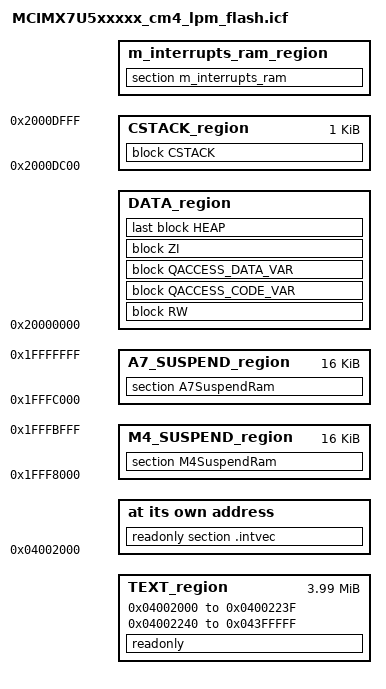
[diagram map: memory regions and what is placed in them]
/*
** ###################################################################
**     Processors:          MCIMX7U5DVK08
**                          MCIMX7U5DVP08
**
**     Compiler:            IAR ANSI C/C++ Compiler for ARM
**     Reference manual:    i.MX7ULPRMV2, Rev. A, Dec. 2017
**     Version:             rev. 5.0, 2017-12-22
**     Build:               b171222
**
**     Abstract:
**         Linker file for the IAR ANSI C/C++ Compiler for ARM
**
**     Copyright 2016 Freescale Semiconductor, Inc.
**     Copyright 2016-2017 NXP
**     All rights reserved.
**
**     SPDX-License-Identifier: BSD-3-Clause
**
**     http:                 www.nxp.com
**     mail:                 support@nxp.com
**
** ###################################################################
*/

/* Memory region from [0x04000000-0x04001FFF] is reserved for ROM header */

define symbol __ram_vector_table_size__ =  isdefinedsymbol(__ram_vector_table__) ? 0x00000240 : 0;
define symbol __ram_vector_table_offset__ =  isdefinedsymbol(__ram_vector_table__) ? 0x0000023F : 0;

define symbol m_interrupts_start       = 0x04002000;
define symbol m_interrupts_end         = 0x0400223F;

define symbol m_text_start             = 0x04002240;
define symbol m_text_end               = 0x043FFFFF;

define symbol m_m4_suspend_ram_start   = 0x1FFF8000;
define symbol m_m4_suspend_ram_end     = 0x1FFFBFFF;

define symbol m_a7_suspend_ram_start   = 0x1FFFC000;
define symbol m_a7_suspend_ram_end     = 0x1FFFFFFF;

define symbol m_interrupts_ram_start   = 0x1FFD2000;
define symbol m_interrupts_ram_end     = 0x1FFD2000 + __ram_vector_table_offset__;

define symbol m_data_start             = m_interrupts_ram_start + __ram_vector_table_size__;
define symbol m_data_end               = 0x1FFF7FFF;

/* 32KB RAM above 0x20008000 is used by ROM. In suspend/resume case, the RAM above 0x20008000
 * will be corrupted by ROM. Application need to save data to somewhere safe, specifically,
 * [0x20008000, 0x2000BFFF] to M4 suspend ram, and [0x2000C000, 0x2000DBFF] to
 * ROM header area [0x1FFD0000-0x1FFD1BFF]. ROM header area [0x1FFD1C00-0x1FFD1FFF] is used
 * for IOMUXC0/GPIOA/GPIOB recovery which must be done before pad isolation ack.
 */
define symbol m_data_2_start           = 0x20000000;
define symbol m_data_2_end             = 0x2000DBFF;

/* Sizes */
if (isdefinedsymbol(__stack_size__)) {
  define symbol __size_cstack__        = __stack_size__;
} else {
  define symbol __size_cstack__        = 0x400;
}

if (isdefinedsymbol(__heap_size__)) {
  define symbol __size_heap__          = __heap_size__;
} else {
  define symbol __size_heap__          = 0x400;
}

define exported symbol __VECTOR_TABLE  = m_interrupts_start;
define exported symbol __VECTOR_RAM    = isdefinedsymbol(__ram_vector_table__) ? m_interrupts_ram_start : m_interrupts_start;
define exported symbol __RAM_VECTOR_TABLE_SIZE = __ram_vector_table_size__;

define memory mem with size = 4G;
define region TEXT_region = mem:[from m_interrupts_start to m_interrupts_end]
                          | mem:[from m_text_start to m_text_end];
define region DATA_region = mem:[from m_data_start to m_data_end]
                          | mem:[from m_data_2_start to m_data_2_end];
define region CSTACK_region = mem:[from m_data_2_end+1 to m_data_2_end+__size_cstack__];
define region m_interrupts_ram_region = mem:[from m_interrupts_ram_start to m_interrupts_ram_end];
define region M4_SUSPEND_region = mem:[from m_m4_suspend_ram_start to m_m4_suspend_ram_end];
define region A7_SUSPEND_region = mem:[from m_a7_suspend_ram_start to m_a7_suspend_ram_end];

define block CSTACK    with alignment = 8, size = __size_cstack__   { };
define block HEAP      with alignment = 8, size = __size_heap__     { };
define block RW        { readwrite };
define block ZI        { zi };
define block QACCESS_CODE_VAR   with alignment = 32 { section CodeQuickAccess };
define block QACCESS_DATA_VAR   with alignment = 32 { section DataQuickAccess };

initialize by copy { readwrite, section .textrw, section DataQuickAccess, section CodeQuickAccess };
do not initialize  { section .noinit, section M4SuspendRam, section A7SuspendRam };

place at address mem: m_interrupts_start    { readonly section .intvec };
place in TEXT_region                        { readonly };
place in DATA_region                        { block RW };
place in DATA_region                        { block QACCESS_CODE_VAR };
place in DATA_region                        { block QACCESS_DATA_VAR };
place in DATA_region                        { block ZI };
place in DATA_region                        { last block HEAP };
place in CSTACK_region                      { block CSTACK };
place in m_interrupts_ram_region            { section m_interrupts_ram };
place in M4_SUSPEND_region                  { section M4SuspendRam };
place in A7_SUSPEND_region                  { section A7SuspendRam };
